AUTOSAR XML (schema 4-0-3)
package /ComponentTypes
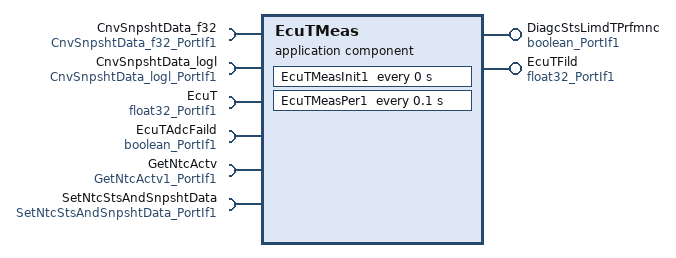
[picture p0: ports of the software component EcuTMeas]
  application sw component type EcuTMeas
    provide port DiagcStsLimdTPrfmnc: nonqueued-sender-com-spec{data-element=Logl, init-value=0}, provided-interface=boolean_PortIf1
    provide port EcuTFild: nonqueued-sender-com-spec{data-element=Val, init-value=25}, provided-interface=float32_PortIf1
    6 x require port:
      CnvSnpshtData_f32: client-com-spec=Oper, required-interface=CnvSnpshtData_f32_PortIf1
      CnvSnpshtData_logl: client-com-spec=Oper, required-interface=CnvSnpshtData_logl_PortIf1
      EcuT: nonqueued-receiver-com-spec{data-element=Val, filter=data-filter-type=ALWAYS, init-value=0}, required-interface=float32_PortIf1
      EcuTAdcFaild: nonqueued-receiver-com-spec{data-element=Logl, filter=data-filter-type=ALWAYS, init-value=0}, required-interface=boolean_PortIf1
      GetNtcActv: client-com-spec=Oper, required-interface=GetNtcActv1_PortIf1
      SetNtcStsAndSnpshtData: client-com-spec=Oper, required-interface=SetNtcStsAndSnpshtData_PortIf1
    behavior EcuTMeas_InternalBehavior
      ar-typed-per-instance-memorys:
        data dEcuTMeasEcuTCalcd: sw-calibration-access=READ-ONLY, type=float32
        data EcuTFilStVari: sw-calibration-access=READ-ONLY, type=FilLpRec1
      timing event EcuTMeas_InitEvent: start-on-event=EcuTMeasInit1, period=0
      timing event TMT_EcuTMeasPer1: start-on-event=EcuTMeasPer1, period=0.1
      runnable EcuTMeasInit1
        data-receive-point-by-arguments:
          access REC_EcuT_Val: accessed-variable=EcuT.Val
        data-send-points:
          access SEND_EcuTFild_Val: accessed-variable=EcuTFild.Val
      runnable EcuTMeasPer1
        data-receive-point-by-arguments:
          access REC_EcuT_Val: accessed-variable=EcuT.Val
          access REC_EcuTAdcFaild_Logl: accessed-variable=EcuTAdcFaild.Logl
        data-send-points:
          access SEND_DiagcStsLimdTPrfmnc_Logl: accessed-variable=DiagcStsLimdTPrfmnc.Logl
          access SEND_EcuTFild_Val: accessed-variable=EcuTFild.Val
        4 x sync call, all with timeout=0:
          SC_CnvSnpshtData_f32_PortIf1_Oper: operation=CnvSnpshtData_f32.Oper
          SC_CnvSnpshtData_logl_PortIf1_Oper: operation=CnvSnpshtData_logl.Oper
          SC_GetNtcActv_Oper: operation=GetNtcActv.Oper
          SC_SetNtcStsAndSnpshtData_Oper: operation=SetNtcStsAndSnpshtData.Oper
  swc implementation EcuTMeas_Implementation: behavior=EcuTMeas_InternalBehavior
    code-descriptors:
      code Default: artifact-descriptors=autosar-engineering-object={short-label=Default, category=SWSRC}
